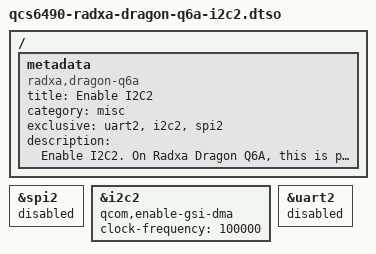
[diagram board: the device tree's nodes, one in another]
// SPDX-License-Identifier: BSD-3-Clause
/*
 * Copyright (c) 2025 Radxa Computer (Shenzhen) Co., Ltd.
 */

/dts-v1/;
/plugin/;

/ {
	metadata {
		title = "Enable I2C2";
		compatible = "radxa,dragon-q6a";
		category = "misc";
		exclusive = "uart2","i2c2","spi2";
		description = "Enable I2C2. 
On Radxa Dragon Q6A, this is pin 28(scl), 27(sda).";
	};
};

&spi2 {
	status = "disabled";
};

&i2c2 {
	qcom,enable-gsi-dma;
	status = "okay";

	clock-frequency = <100000>;
};

&uart2 {
	status = "disabled";
};
